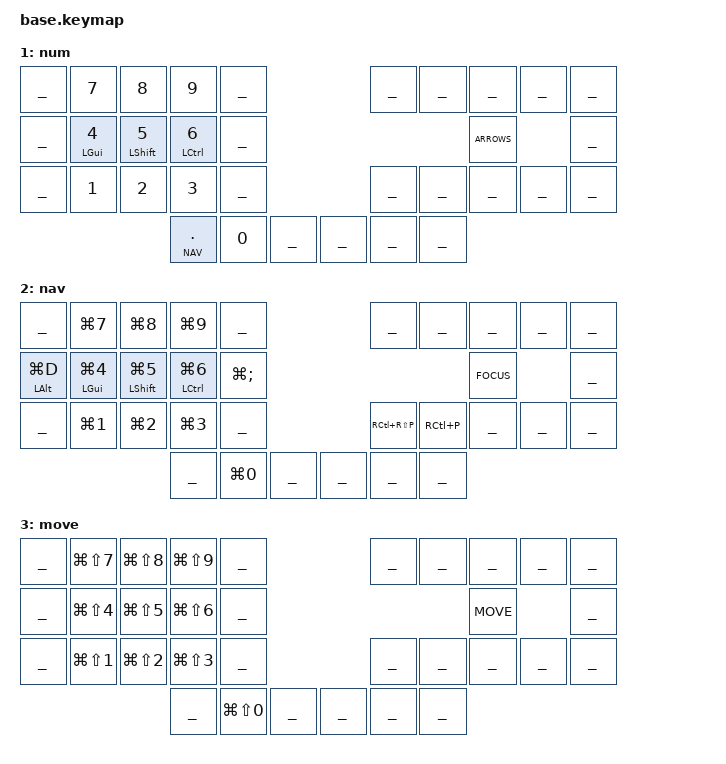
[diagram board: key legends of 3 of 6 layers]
#include <behaviors.dtsi>
#include <dt-bindings/zmk/bt.h>
#include <dt-bindings/zmk/keys.h>
#include <dt-bindings/zmk/outputs.h>

#define BASE    0
#define NUM     1
#define NAV     2
#define MV      3
#define UTIL    4
#define FKEY    5

#include "shared/setup.dtsi"
#include "shared/macros.dtsi"
#include "shared/behaviors.dtsi"
#include "shared/combos.dtsi"

/ {
    keymap {
        compatible = "zmk,keymap";
        base {
            display-name = "base";
            bindings = <
//          ╭───────────────────┬───────────────────┬───────────────────┬───────────────────┬───────────────────╮                                           ╭───────────────────┬───────────────────┬───────────────────┬───────────────────┬───────────────────╮
              &kp Q               &kp W               &kp E               &kp R               &kp T                                                           &kp Y               &kp U               &kp I               &kp O               &kp P              
//          ├───────────────────┼───────────────────┼───────────────────┼───────────────────┼───────────────────┤                                           ├───────────────────┼───────────────────┼───────────────────┼───────────────────┼───────────────────┤
              &hml LALT A         &hml LGUI S         &hml LSHIFT D       &hml LCTRL F        &kp G                                                           &kp H               &hmr RCTRL J        &hmr RSHIFT K       &hmr RGUI L         &hmr RALT SQT    
//          ├───────────────────┼───────────────────┼───────────────────┼───────────────────┼───────────────────┤                                           ├───────────────────┼───────────────────┼───────────────────┼───────────────────┼───────────────────┤
              &kp Z               &kp X               &kp C               &kp V               &kp B                                                           &kp N               &kp M               &comma_semi         &dot_colon          &qexcl             
//          ╰───────────────────┴───────────────────┴───────────────────┼───────────────────┼───────────────────┼───────────────────╮   ╭───────────────────┼───────────────────┼───────────────────┼───────────────────┴───────────────────┴───────────────────╯
                                                                          &nav                &smart_shft         &kp SPACE               &kp RET             &kp BSPC            &lt NUM K_CANCEL                                                               
//                                                                      ╰───────────────────┴───────────────────┴───────────────────╯   ╰───────────────────┴───────────────────┴───────────────────╯                                                            
            >;
        };

        num {
            display-name = "num";
            bindings = <
//          ╭───────────────────┬───────────────────┬───────────────────┬───────────────────┬───────────────────╮                                           ╭───────────────────┬───────────────────┬───────────────────┬───────────────────┬───────────────────╮
              ___                 &kp N7              &kp N8              &kp N9              ___                                                             ___                 ___                 ___                 ___                 ___                
//          ├───────────────────┼───────────────────┼───────────────────┼───────────────────┼───────────────────┤                                           ├───────────────────┼───────────────────┼───────────────────┼───────────────────┼───────────────────┤
              ___                 &hml LGUI N4        &hml LSHIFT N5      &hml LCTRL N6       ___                                                                                                 ARROWS                                      ___                
//          ├───────────────────┼───────────────────┼───────────────────┼───────────────────┼───────────────────┤                                           ├───────────────────┼───────────────────┼───────────────────┼───────────────────┼───────────────────┤
              ___                 &kp N1              &kp N2              &kp N3              ___                                                             ___                 ___                 ___                 ___                 ___                
//          ╰───────────────────┴───────────────────┴───────────────────┼───────────────────┼───────────────────┼───────────────────╮   ╭───────────────────┼───────────────────┼───────────────────┼───────────────────┴───────────────────┴───────────────────╯
                                                                          &lt NAV DOT         &kp N0              ___                     ___                 ___                 ___                                                                            
//                                                                      ╰───────────────────┴───────────────────┴───────────────────╯   ╰───────────────────┴───────────────────┴───────────────────╯                                                            
            >;
        };

        nav {
            display-name = "nav";
            bindings = <
//          ╭───────────────────┬───────────────────┬───────────────────┬───────────────────┬───────────────────╮                                           ╭───────────────────┬───────────────────┬───────────────────┬───────────────────┬───────────────────╮
              ___                 &kp LG(N7)          &kp LG(N8)          &kp LG(N9)          ___                                                             ___                 ___                 ___                 ___                 ___                
//          ├───────────────────┼───────────────────┼───────────────────┼───────────────────┼───────────────────┤                                           ├───────────────────┼───────────────────┼───────────────────┼───────────────────┼───────────────────┤
              &hml LALT LG(D)     &hml LGUI LG(N4)    &hml LSHIFT LG(N5)  &hml LCTRL LG(N6)   &kp LG(SEMI)                                                                                         FOCUS                                      ___                
//          ├───────────────────┼───────────────────┼───────────────────┼───────────────────┼───────────────────┤                                           ├───────────────────┼───────────────────┼───────────────────┼───────────────────┼───────────────────┤
              ___                 &kp LG(N1)          &kp LG(N2)          &kp LG(N3)          ___                                                             &kp RC(RS(P))       &kp RC(P)           ___                 ___                 ___                
//          ╰───────────────────┴───────────────────┴───────────────────┼───────────────────┼───────────────────┼───────────────────╮   ╭───────────────────┼───────────────────┼───────────────────┼───────────────────┴───────────────────┴───────────────────╯
                                                                          ___                 &kp LG(N0)          ___                     ___                 ___                 ___                                                                            
//                                                                      ╰───────────────────┴───────────────────┴───────────────────╯   ╰───────────────────┴───────────────────┴───────────────────╯                                                            
            >;
        };

        mv {
            display-name = "move";
            bindings = <
//          ╭───────────────────┬───────────────────┬───────────────────┬───────────────────┬───────────────────╮                                           ╭───────────────────┬───────────────────┬───────────────────┬───────────────────┬───────────────────╮
              ___                 &kp LG(LS(N7))      &kp LG(LS(N8))      &kp LG(LS(N9))      ___                                                             ___                 ___                 ___                 ___                 ___                
//          ├───────────────────┼───────────────────┼───────────────────┼───────────────────┼───────────────────┤                                           ├───────────────────┼───────────────────┼───────────────────┼───────────────────┼───────────────────┤
              ___                 &kp LG(LS(N4))      &kp LG(LS(N5))      &kp LG(LS(N6))      ___                                                                                                  MOVE                                       ___                
//          ├───────────────────┼───────────────────┼───────────────────┼───────────────────┼───────────────────┤                                           ├───────────────────┼───────────────────┼───────────────────┼───────────────────┼───────────────────┤
              ___                 &kp LG(LS(N1))      &kp LG(LS(N2))      &kp LG(LS(N3))      ___                                                             ___                 ___                 ___                 ___                 ___                
//          ╰───────────────────┴───────────────────┴───────────────────┼───────────────────┼───────────────────┼───────────────────╮   ╭───────────────────┼───────────────────┼───────────────────┼───────────────────┴───────────────────┴───────────────────╯
                                                                          ___                 &kp LG(LS(N0))      ___                     ___                 ___                 ___                                                                            
//                                                                      ╰───────────────────┴───────────────────┴───────────────────╯   ╰───────────────────┴───────────────────┴───────────────────╯                                                            
            >;
        };

        util {
            display-name = "util";
            bindings = <
//          ╭───────────────────┬───────────────────┬───────────────────┬───────────────────┬───────────────────╮                                           ╭───────────────────┬───────────────────┬───────────────────┬───────────────────┬───────────────────╮
              ___                 ___                 ___                 ___                 &bootloader                                                     &bootloader         &kp C_PREV          &kp C_PLAY_PAUSE    &kp C_NEXT          ___
//          ├───────────────────┼───────────────────┼───────────────────┼───────────────────┼───────────────────┤                                           ├───────────────────┼───────────────────┼───────────────────┼───────────────────┼───────────────────┤
              &out OUT_BLE        &bt BT_SEL 3        &kp C_BRI_UP        &kp C_BRI_DN        &bt BT_CLR                                                      ___                 &kp C_VOL_DN        &kp C_VOL_UP        &kp C_MUTE          ___
//          ├───────────────────┼───────────────────┼───────────────────┼───────────────────┼───────────────────┤                                           ├───────────────────┼───────────────────┼───────────────────┼───────────────────┼───────────────────┤
              &out OUT_USB        &bt BT_SEL 0        &bt BT_SEL 1        &bt BT_SEL 2        ___                                                             ___                 &kp RC(RS(RA(M)))   ___                 ___                 ___
//          ╰───────────────────┴───────────────────┴───────────────────┼───────────────────┼───────────────────┼───────────────────╮   ╭───────────────────┼───────────────────┼───────────────────┼───────────────────┴───────────────────┴───────────────────╯
                                                                          ___                 ___                 ___                     ___                 ___                 ___
//                                                                      ╰───────────────────┴───────────────────┴───────────────────╯   ╰───────────────────┴───────────────────┴───────────────────╯
            >;
        };

        fkey {
            display-name = "fkey";
            bindings = <
//          ╭───────────────────┬───────────────────┬───────────────────┬───────────────────┬───────────────────╮                                           ╭───────────────────┬───────────────────┬───────────────────┬───────────────────┬───────────────────╮
              ___                 &kp F7              &kp F8              &kp F9              ___                                                             ___                 ___                 ___                 ___                 ___
//          ├───────────────────┼───────────────────┼───────────────────┼───────────────────┼───────────────────┤                                           ├───────────────────┼───────────────────┼───────────────────┼───────────────────┼───────────────────┤
              ___                 &kp F4              &kp F5              &kp F6              ___                                                             ___                 ___                 ___                 ___                 ___
//          ├───────────────────┼───────────────────┼───────────────────┼───────────────────┼───────────────────┤                                           ├───────────────────┼───────────────────┼───────────────────┼───────────────────┼───────────────────┤
              ___                 &kp F1              &kp F2              &kp F3              ___                                                             ___                 &kp F10             &kp F11             &kp F12             ___
//          ╰───────────────────┴───────────────────┴───────────────────┼───────────────────┼───────────────────┼───────────────────╮   ╭───────────────────┼───────────────────┼───────────────────┼───────────────────┴───────────────────┴───────────────────╯
                                                                          ___                 ___                 ___                     ___                 ___                 ___
//                                                                      ╰───────────────────┴───────────────────┴───────────────────╯   ╰───────────────────┴───────────────────┴───────────────────╯
            >;
        };
    };
};
